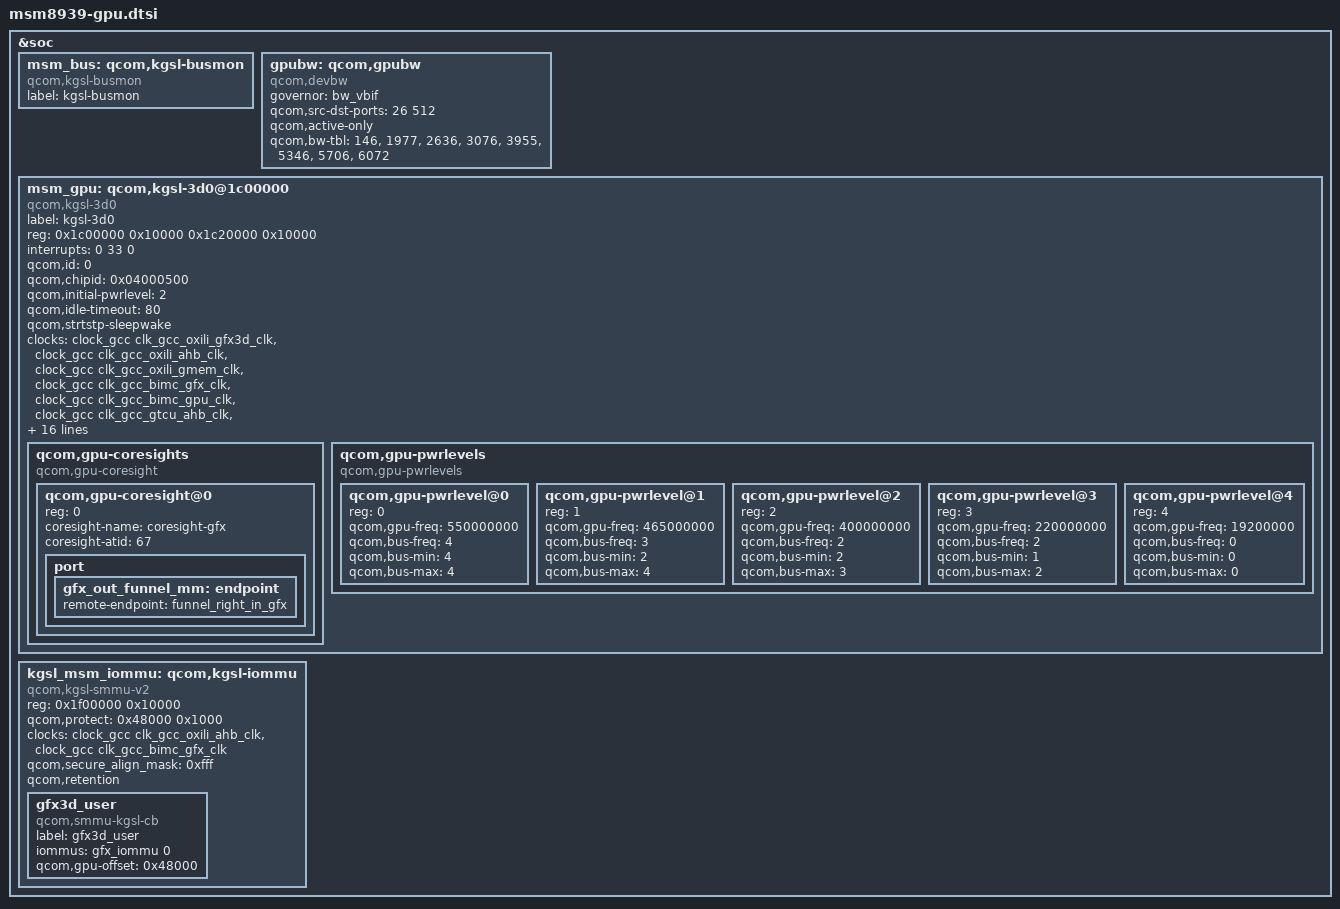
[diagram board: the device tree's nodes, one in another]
/* Copyright (c) 2014-2015, 2018, The Linux Foundation. All rights reserved.
 *
 * This program is free software; you can redistribute it and/or modify
 * it under the terms of the GNU General Public License version 2 and
 * only version 2 as published by the Free Software Foundation.
 *
 * This program is distributed in the hope that it will be useful,
 * but WITHOUT ANY WARRANTY; without even the implied warranty of
 * MERCHANTABILITY or FITNESS FOR A PARTICULAR PURPOSE.  See the
 * GNU General Public License for more details.
 */

&soc {
	msm_bus: qcom,kgsl-busmon {
		label = "kgsl-busmon";
		compatible = "qcom,kgsl-busmon";
	};

	/* To use BIMC based bus governor */
	gpubw: qcom,gpubw {
		compatible = "qcom,devbw";
		governor = "bw_vbif";
		qcom,src-dst-ports = <26 512>;

		/*
		 * active-only flag is used while registering the bus
		 * governor.It helps release the bus vote when the CPU
		 * subsystem is inactiv3
		 */
		qcom,active-only;
		qcom,bw-tbl =
			< 146 >,	/* 9.6 MHz */
			< 1977 >,	/* 129.6 MHz */
			< 2636 >,	/* 172.8 MHz */
			< 3076 >,	/* 201.6 MHz */
			< 3955 >,	/* 259.2 MHz */
			< 5346 >,	/* 350.4 MHz */
			< 5706 >,	/* 374.0 MHz */
			< 6072 >;	/* 398.4 MHz */
	};

	msm_gpu: qcom,kgsl-3d0@1c00000 {
		label = "kgsl-3d0";
		compatible = "qcom,kgsl-3d0", "qcom,kgsl-3d";
		reg = <0x1c00000 0x10000
		       0x1c20000 0x10000>;
		reg-names = "kgsl_3d0_reg_memory", "kgsl_3d0_shader_memory";
		interrupts = <0 33 0>;
		interrupt-names = "kgsl_3d0_irq";
		qcom,id = <0>;
		qcom,chipid = <0x04000500>;

		qcom,initial-pwrlevel = <2>;

		qcom,idle-timeout = <80>; //msecs
		qcom,strtstp-sleepwake;

		clocks = <&clock_gcc clk_gcc_oxili_gfx3d_clk>,
		         <&clock_gcc clk_gcc_oxili_ahb_clk>,
		         <&clock_gcc clk_gcc_oxili_gmem_clk>,
		         <&clock_gcc clk_gcc_bimc_gfx_clk>,
		         <&clock_gcc clk_gcc_bimc_gpu_clk>,
		         <&clock_gcc clk_gcc_gtcu_ahb_clk>,
			 <&clock_gcc clk_gcc_gfx_tcu_clk>,
			 <&clock_gcc clk_gcc_gfx_tbu_clk>,
			 <&clock_gcc clk_gcc_oxili_timer_clk>;

		clock-names = "core_clk", "iface_clk", "mem_clk",
		              "mem_iface_clk", "alt_mem_iface_clk",
		              "gtcu_iface_clk", "gtcu_clk", "gtbu_clk",
		              "rbbmtimer_clk";

		/* Bus Scale Settings */
		qcom,gpubw-dev = <&gpubw>;
		qcom,bus-control;
		qcom,bus-width = <16>;
		qcom,msm-bus,name = "grp3d";
		qcom,msm-bus,num-cases = <5>;
		qcom,msm-bus,num-paths = <1>;
		qcom,msm-bus,vectors-KBps =
		        <26 512 0 0>,
		        <26 512 0 2764000>,
		        <26 512 0 5600000>,
		        <26 512 0 5984000>,
		        <26 512 0 6368000>;

		regulator-names = "vdd";
		/* GDSC oxili regulators */
		vdd-supply = <&gdsc_oxili_gx>;

		/* CPU latency parameter */
		qcom,pm-qos-active-latency = <401>;
		qcom,pm-qos-wakeup-latency = <401>;

		qcom,gpu-coresights {
			#address-cells = <1>;
			#size-cells = <0>;
			compatible = "qcom,gpu-coresight";

			/* Trace bus */
			qcom,gpu-coresight@0 {
				reg = <0>;
				coresight-name = "coresight-gfx";
				coresight-atid = <67>;
				port {
					gfx_out_funnel_mm: endpoint {
						remote-endpoint =
						<&funnel_right_in_gfx>;
					};
				};
			};
		};

		/* Power levels */
		qcom,gpu-pwrlevels {
			#address-cells = <1>;
			#size-cells = <0>;

			compatible = "qcom,gpu-pwrlevels";

			qcom,gpu-pwrlevel@0 {
				reg = <0>;
				qcom,gpu-freq = <550000000>;
				qcom,bus-freq = <4>;
				qcom,bus-min = <4>;
				qcom,bus-max = <4>;
			};

			qcom,gpu-pwrlevel@1 {
				reg = <1>;
				qcom,gpu-freq = <465000000>;
				qcom,bus-freq = <3>;
				qcom,bus-min = <2>;
				qcom,bus-max = <4>;
			};

			qcom,gpu-pwrlevel@2 {
				reg = <2>;
				qcom,gpu-freq = <400000000>;
				qcom,bus-freq = <2>;
				qcom,bus-min = <2>;
				qcom,bus-max = <3>;
			};

			qcom,gpu-pwrlevel@3 {
				reg = <3>;
				qcom,gpu-freq = <220000000>;
				qcom,bus-freq = <2>;
				qcom,bus-min = <1>;
				qcom,bus-max = <2>;
			};

			qcom,gpu-pwrlevel@4 {
				reg = <4>;
				qcom,gpu-freq = <19200000>;
				qcom,bus-freq = <0>;
				qcom,bus-min = <0>;
				qcom,bus-max = <0>;
			};
		};
	};

	kgsl_msm_iommu: qcom,kgsl-iommu {
		compatible = "qcom,kgsl-smmu-v2";
		reg = <0x1f00000 0x10000>;
		qcom,protect = <0x48000 0x1000>;

		clocks = <&clock_gcc clk_gcc_oxili_ahb_clk>,
			 <&clock_gcc clk_gcc_bimc_gfx_clk>;

		clock-names = "gpu_ahb_clk", "gcc_bimc_gfx_clk";

		qcom,secure_align_mask = <0xfff>;
		qcom,retention;

		gfx3d_user: gfx3d_user {
			compatible = "qcom,smmu-kgsl-cb";
			label = "gfx3d_user";
			iommus = <&gfx_iommu 0>;
			qcom,gpu-offset = <0x48000>;
		};
	};
};
